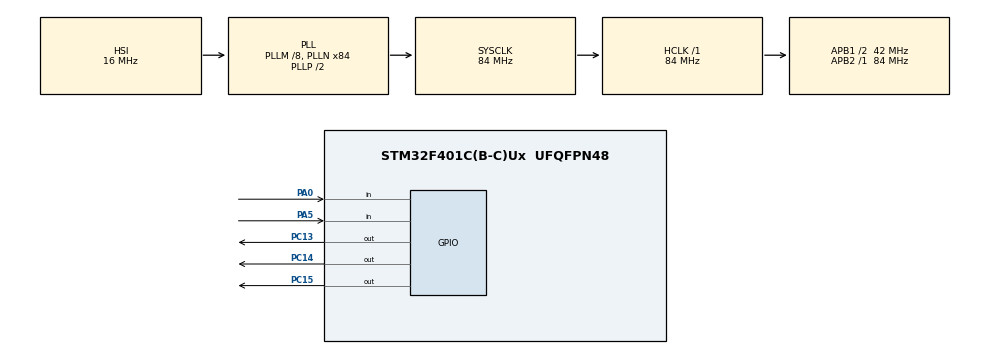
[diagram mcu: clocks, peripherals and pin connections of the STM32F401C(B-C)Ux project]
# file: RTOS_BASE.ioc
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FREERTOS.Tasks01=defaultTask,24,128,StartDefaultTask,Default,NULL,Dynamic,NULL,NULL
Mcu.Family=STM32F4
Mcu.Name=STM32F401C(B-C)Ux
Mcu.Package=UFQFPN48
NVIC.PriorityGroup=NVIC_PRIORITYGROUP_4
NVIC.TIM5_IRQn=true\:15\:0\:false\:false\:true\:false\:false\:true\:true
NVIC.TimeBase=TIM5_IRQn
NVIC.TimeBaseIP=TIM5
PA0-WKUP.Signal=GPIO_Input
PA13.Mode=Serial_Wire
PA13.Signal=SYS_JTMS-SWDIO
PA14.Mode=Serial_Wire
PA14.Signal=SYS_JTCK-SWCLK
PA5.Signal=GPIO_Input
PC13-ANTI_TAMP.Signal=GPIO_Output
PC14-OSC32_IN.Signal=GPIO_Output
PC15-OSC32_OUT.Signal=GPIO_Output
ProjectManager.HeapSize=0x200
ProjectManager.StackSize=0x400
ProjectManager.TargetToolchain=STM32CubeIDE
RCC.48MHZClocksFreq_Value=42000000
RCC.AHBFreq_Value=84000000
RCC.APB1CLKDivider=RCC_HCLK_DIV2
RCC.APB1Freq_Value=42000000
RCC.APB1TimFreq_Value=84000000
RCC.APB2Freq_Value=84000000
RCC.APB2TimFreq_Value=84000000
RCC.CortexFreq_Value=84000000
RCC.HCLKFreq_Value=84000000
RCC.HSE_VALUE=25000000
RCC.HSI_VALUE=16000000
RCC.LSE_VALUE=32768
RCC.PLLM=8
RCC.PLLN=84
RCC.SYSCLKFreq_VALUE=84000000
RCC.SYSCLKSource=RCC_SYSCLKSOURCE_PLLCLK
RCC.VCOOutputFreq_Value=168000000
VP_FREERTOS_VS_CMSIS_V2.Mode=CMSIS_V2
VP_SYS_VS_tim5.Mode=TIM5
board=custom

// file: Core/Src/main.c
/* USER CODE BEGIN Header */
/**
  ******************************************************************************
  * @file           : main.c
  * @brief          : Main program body
  ******************************************************************************
  * @attention
  *
  * Copyright (c) 2026 STMicroelectronics.
  * All rights reserved.
  *
  * This software is licensed under terms that can be found in the LICENSE file
  * in the root directory of this software component.
  * If no LICENSE file comes with this software, it is provided AS-IS.
  *
  ******************************************************************************
  */
/* USER CODE END Header */
#include "main.h"
#include "cmsis_os.h"

/* USER CODE BEGIN Includes */
#include "FreeRTOS.h"
#include "timers.h"
/* USER CODE END Includes */

/* Definitions for defaultTask */

void SystemClock_Config(void);
static void MX_GPIO_Init(void);
void timcallback();
void task1(void *argument);

/* USER CODE BEGIN 0 */
xTimerHandle stim;
/* USER CODE END 0 */

int main(void)
{

  /* MCU Configuration--------------------------------------------------------*/

  /* Reset of all peripherals, Initializes the Flash interface and the Systick. */
  HAL_Init();

  /* Configure the system clock */
  SystemClock_Config();

  /* Initialize all configured peripherals */
  MX_GPIO_Init();

  /* Init scheduler */
  osKernelInitialize();

  /* Create the thread(s) */
  /* creation of defaultTask */
  stim = xTimerCreate( "softimer",
    1000,
    pdFALSE,
    NULL,
    timcallback);

    xTaskCreate(task1,"task" , 128, NULL, 2, NULL);
    xTimerStart(stim,0);

  /* Start scheduler */
  osKernelStart();

  /* We should never get here as control is now taken by the scheduler */

  /* Infinite loop */
  while (1)
  {

  }
}

void SystemClock_Config(void)
{
  RCC_OscInitTypeDef RCC_OscInitStruct = {0};
  RCC_ClkInitTypeDef RCC_ClkInitStruct = {0};

  /** Configure the main internal regulator output voltage
  */
  __HAL_RCC_PWR_CLK_ENABLE();
  __HAL_PWR_VOLTAGESCALING_CONFIG(PWR_REGULATOR_VOLTAGE_SCALE2);

  /** Initializes the RCC Oscillators according to the specified parameters
  * in the RCC_OscInitTypeDef structure.
  */
  RCC_OscInitStruct.OscillatorType = RCC_OSCILLATORTYPE_HSI;
  RCC_OscInitStruct.HSIState = RCC_HSI_ON;
  RCC_OscInitStruct.HSICalibrationValue = RCC_HSICALIBRATION_DEFAULT;
  RCC_OscInitStruct.PLL.PLLState = RCC_PLL_ON;
  RCC_OscInitStruct.PLL.PLLSource = RCC_PLLSOURCE_HSI;
  RCC_OscInitStruct.PLL.PLLM = 8;
  RCC_OscInitStruct.PLL.PLLN = 84;
  RCC_OscInitStruct.PLL.PLLP = RCC_PLLP_DIV2;
  RCC_OscInitStruct.PLL.PLLQ = 4;
  if (HAL_RCC_OscConfig(&RCC_OscInitStruct) != HAL_OK)
  {
    Error_Handler();
  }

  /** Initializes the CPU, AHB and APB buses clocks
  */
  RCC_ClkInitStruct.ClockType = RCC_CLOCKTYPE_HCLK|RCC_CLOCKTYPE_SYSCLK
                              |RCC_CLOCKTYPE_PCLK1|RCC_CLOCKTYPE_PCLK2;
  RCC_ClkInitStruct.SYSCLKSource = RCC_SYSCLKSOURCE_PLLCLK;
  RCC_ClkInitStruct.AHBCLKDivider = RCC_SYSCLK_DIV1;
  RCC_ClkInitStruct.APB1CLKDivider = RCC_HCLK_DIV2;
  RCC_ClkInitStruct.APB2CLKDivider = RCC_HCLK_DIV1;

  if (HAL_RCC_ClockConfig(&RCC_ClkInitStruct, FLASH_LATENCY_2) != HAL_OK)
  {
    Error_Handler();
  }
}

static void MX_GPIO_Init(void)
{
  GPIO_InitTypeDef GPIO_InitStruct = {0};

  /* GPIO Ports Clock Enable */
  __HAL_RCC_GPIOC_CLK_ENABLE();
  __HAL_RCC_GPIOA_CLK_ENABLE();

  /*Configure GPIO pin Output Level */
  HAL_GPIO_WritePin(GPIOC, GPIO_PIN_13|GPIO_PIN_14|GPIO_PIN_15, GPIO_PIN_RESET);

  /*Configure GPIO pins : PC13 PC14 PC15 */
  GPIO_InitStruct.Pin = GPIO_PIN_13|GPIO_PIN_14|GPIO_PIN_15;
  GPIO_InitStruct.Mode = GPIO_MODE_OUTPUT_PP;
  GPIO_InitStruct.Pull = GPIO_NOPULL;
  GPIO_InitStruct.Speed = GPIO_SPEED_FREQ_LOW;
  HAL_GPIO_Init(GPIOC, &GPIO_InitStruct);

  /*Configure GPIO pins : PA0 PA5 */
  GPIO_InitStruct.Pin = GPIO_PIN_0|GPIO_PIN_5;
  GPIO_InitStruct.Mode = GPIO_MODE_INPUT;
  GPIO_InitStruct.Pull = GPIO_PULLDOWN;
  HAL_GPIO_Init(GPIOA, &GPIO_InitStruct);

}

void task1(void *argument)
{
  /* USER CODE BEGIN 5 */
  /* Infinite loop */
while(1){
	if(HAL_GPIO_ReadPin(GPIOA, GPIO_PIN_5)){
		HAL_GPIO_WritePin(GPIOC, GPIO_PIN_13, GPIO_PIN_RESET);
		xTimerReset( stim, 0 );
	}
	vTaskDelay(100);
}
  /* USER CODE END 5 */
}

void timcallback(){
	HAL_GPIO_WritePin(GPIOC, GPIO_PIN_13, GPIO_PIN_SET);

}

void HAL_TIM_PeriodElapsedCallback(TIM_HandleTypeDef *htim)
{
  if (htim->Instance == TIM5)
  {
    HAL_IncTick();
  }
}

void Error_Handler(void)
{
  __disable_irq();
  while (1)
  {
  }
}
